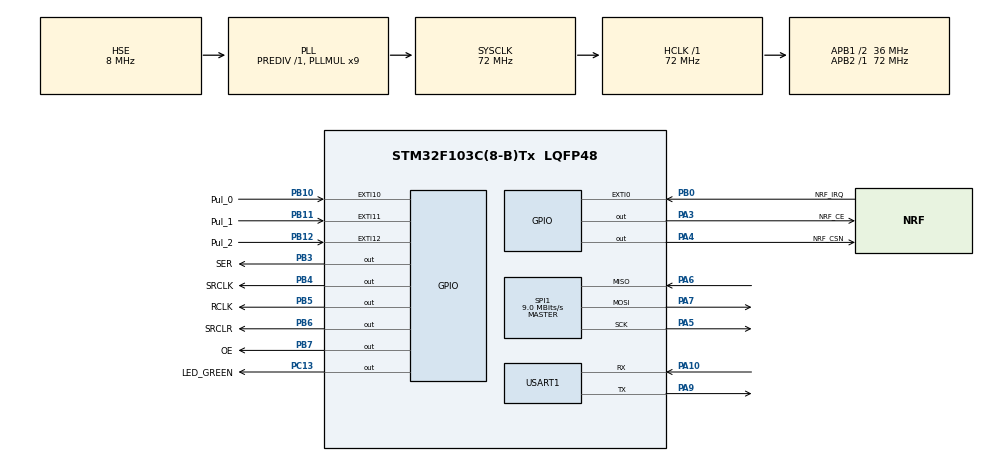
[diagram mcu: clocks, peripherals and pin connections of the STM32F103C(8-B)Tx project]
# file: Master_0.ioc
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Dma.Request0=SPI1_RX
Dma.Request1=SPI1_TX
Dma.Request2=USART1_TX
Dma.SPI1_RX.0.Direction=DMA_PERIPH_TO_MEMORY
Dma.SPI1_RX.0.Instance=DMA1_Channel2
Dma.SPI1_RX.0.MemDataAlignment=DMA_MDATAALIGN_BYTE
Dma.SPI1_RX.0.MemInc=DMA_MINC_ENABLE
Dma.SPI1_RX.0.Mode=DMA_NORMAL
Dma.SPI1_RX.0.PeriphDataAlignment=DMA_PDATAALIGN_BYTE
Dma.SPI1_RX.0.PeriphInc=DMA_PINC_DISABLE
Dma.SPI1_RX.0.Priority=DMA_PRIORITY_LOW
Dma.SPI1_TX.1.Direction=DMA_MEMORY_TO_PERIPH
Dma.SPI1_TX.1.Instance=DMA1_Channel3
Dma.SPI1_TX.1.MemDataAlignment=DMA_MDATAALIGN_BYTE
Dma.SPI1_TX.1.MemInc=DMA_MINC_ENABLE
Dma.SPI1_TX.1.Mode=DMA_NORMAL
Dma.SPI1_TX.1.PeriphDataAlignment=DMA_PDATAALIGN_BYTE
Dma.SPI1_TX.1.PeriphInc=DMA_PINC_DISABLE
Dma.SPI1_TX.1.Priority=DMA_PRIORITY_LOW
Dma.USART1_TX.2.Direction=DMA_MEMORY_TO_PERIPH
Dma.USART1_TX.2.Instance=DMA1_Channel4
Dma.USART1_TX.2.MemDataAlignment=DMA_MDATAALIGN_BYTE
Dma.USART1_TX.2.MemInc=DMA_MINC_ENABLE
Dma.USART1_TX.2.Mode=DMA_NORMAL
Dma.USART1_TX.2.PeriphDataAlignment=DMA_PDATAALIGN_BYTE
Dma.USART1_TX.2.PeriphInc=DMA_PINC_DISABLE
Dma.USART1_TX.2.Priority=DMA_PRIORITY_LOW
Mcu.Family=STM32F1
Mcu.Name=STM32F103C(8-B)Tx
Mcu.Package=LQFP48
NVIC.DMA1_Channel2_IRQn=true\:0\:0\:false\:false\:true\:false\:true\:true
NVIC.DMA1_Channel3_IRQn=true\:0\:0\:false\:false\:true\:false\:true\:true
NVIC.DMA1_Channel4_IRQn=true\:0\:0\:false\:false\:true\:false\:true\:true
NVIC.EXTI0_IRQn=true\:0\:0\:false\:false\:true\:true\:true\:true
NVIC.EXTI15_10_IRQn=true\:0\:0\:false\:false\:true\:true\:true\:true
NVIC.PriorityGroup=NVIC_PRIORITYGROUP_4
NVIC.USART1_IRQn=true\:0\:0\:false\:false\:true\:false\:true\:true
PA10.Mode=Asynchronous
PA10.Signal=USART1_RX
PA13.Mode=Serial_Wire
PA13.Signal=SYS_JTMS-SWDIO
PA14.Mode=Serial_Wire
PA14.Signal=SYS_JTCK-SWCLK
PA3.GPIO_Label=NRF_CE
PA3.Signal=GPIO_Output
PA4.GPIO_Label=NRF_CSN
PA4.GPIO_Speed=GPIO_SPEED_FREQ_LOW
PA4.PinState=GPIO_PIN_SET
PA4.Signal=GPIO_Output
PA5.Mode=Full_Duplex_Master
PA5.Signal=SPI1_SCK
PA6.Mode=Full_Duplex_Master
PA6.Signal=SPI1_MISO
PA7.Mode=Full_Duplex_Master
PA7.Signal=SPI1_MOSI
PA9.Mode=Asynchronous
PA9.Signal=USART1_TX
PB0.GPIO_Label=NRF_IRQ
PB0.GPIO_ModeDefaultEXTI=GPIO_MODE_IT_FALLING
PB0.GPIO_PuPd=GPIO_PULLUP
PB0.Signal=GPXTI0
PB10.GPIO_Label=Pul_0
PB10.GPIO_ModeDefaultEXTI=GPIO_MODE_IT_FALLING
PB10.GPIO_PuPd=GPIO_PULLUP
PB10.Signal=GPXTI10
PB11.GPIO_Label=Pul_1
PB11.GPIO_ModeDefaultEXTI=GPIO_MODE_IT_FALLING
PB11.GPIO_PuPd=GPIO_PULLUP
PB11.Signal=GPXTI11
PB12.GPIO_Label=Pul_2
PB12.GPIO_ModeDefaultEXTI=GPIO_MODE_IT_FALLING
PB12.GPIO_PuPd=GPIO_PULLUP
PB12.Signal=GPXTI12
PB3.GPIO_Label=SER
PB3.Signal=GPIO_Output
PB4.GPIO_Label=SRCLK
PB4.Signal=GPIO_Output
PB5.GPIO_Label=RCLK
PB5.Signal=GPIO_Output
PB6.GPIO_Label=SRCLR
PB6.PinState=GPIO_PIN_SET
PB6.Signal=GPIO_Output
PB7.GPIO_Label=OE
PB7.Signal=GPIO_Output
PC13-TAMPER-RTC.GPIO_Label=LED_GREEN
PC13-TAMPER-RTC.Signal=GPIO_Output
PD0-OSC_IN.Mode=HSE-External-Oscillator
PD0-OSC_IN.Signal=RCC_OSC_IN
PD1-OSC_OUT.Mode=HSE-External-Oscillator
PD1-OSC_OUT.Signal=RCC_OSC_OUT
ProjectManager.HeapSize=0x200
ProjectManager.StackSize=0x400
ProjectManager.TargetToolchain=STM32CubeIDE
RCC.AHBFreq_Value=72000000
RCC.APB1CLKDivider=RCC_HCLK_DIV2
RCC.APB1Freq_Value=36000000
RCC.APB1TimFreq_Value=72000000
RCC.APB2Freq_Value=72000000
RCC.APB2TimFreq_Value=72000000
RCC.HCLKFreq_Value=72000000
RCC.PLLMUL=RCC_PLL_MUL9
RCC.PLLSourceVirtual=RCC_PLLSOURCE_HSE
RCC.SYSCLKFreq_VALUE=72000000
RCC.SYSCLKSource=RCC_SYSCLKSOURCE_PLLCLK
RCC.USBFreq_Value=72000000
SPI1.BaudRatePrescaler=SPI_BAUDRATEPRESCALER_8
SPI1.CalculateBaudRate=9.0 MBits/s
SPI1.Direction=SPI_DIRECTION_2LINES
SPI1.Mode=SPI_MODE_MASTER
SPI1.VirtualType=VM_MASTER
USART1.VirtualMode=VM_ASYNC
board=custom

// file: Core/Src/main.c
/* USER CODE BEGIN Header */
/**
  ******************************************************************************
  * @file           : main.c
  * @brief          : Main program body
  ******************************************************************************
  * @attention
  *
  * Copyright (c) 2026 STMicroelectronics.
  * All rights reserved.
  *
  * This software is licensed under terms that can be found in the LICENSE file
  * in the root directory of this software component.
  * If no LICENSE file comes with this software, it is provided AS-IS.
  *
  *
  * 					MASTER
  *
  ******************************************************************************
  */
/* USER CODE END Header */
#include "main.h"
#include "dma.h"
#include "spi.h"
#include "usart.h"
#include "gpio.h"
#include "ports_master.h"

/* USER CODE BEGIN Includes */
#include "API_display.h"
#include "nrf24l01.h"
#include "API_parser.h"
/* USER CODE END Includes */

void SystemClock_Config(void);

int main(void)
{

  /* MCU Configuration--------------------------------------------------------*/

  /* Reset of all peripherals, Initializes the Flash interface and the Systick. */
  HAL_Init();
  HAL_Delay(300);			//Retardo bloqueante para darle tiempo a las fuentes que se estabilicen

  /* Configure the system clock */
  SystemClock_Config();

  /* Initialize all configured peripherals */
  MX_GPIO_Init();
  MX_DMA_Init();
  MX_SPI1_Init();
  MX_USART1_UART_Init();
  /* USER CODE BEGIN 2 */

  initParser(&huart1, &hspi1);

  /* USER CODE END 2 */

  /* Infinite loop */
  while (1)
  {

    /* USER CODE BEGIN 3 */
	  parserUpdate();
  }
  /* USER CODE END 3 */
}

void SystemClock_Config(void)
{
  RCC_OscInitTypeDef RCC_OscInitStruct = {0};
  RCC_ClkInitTypeDef RCC_ClkInitStruct = {0};

  /** Initializes the RCC Oscillators according to the specified parameters
  * in the RCC_OscInitTypeDef structure.
  */
  RCC_OscInitStruct.OscillatorType = RCC_OSCILLATORTYPE_HSE;
  RCC_OscInitStruct.HSEState = RCC_HSE_ON;
  RCC_OscInitStruct.HSEPredivValue = RCC_HSE_PREDIV_DIV1;
  RCC_OscInitStruct.HSIState = RCC_HSI_ON;
  RCC_OscInitStruct.PLL.PLLState = RCC_PLL_ON;
  RCC_OscInitStruct.PLL.PLLSource = RCC_PLLSOURCE_HSE;
  RCC_OscInitStruct.PLL.PLLMUL = RCC_PLL_MUL9;
  if (HAL_RCC_OscConfig(&RCC_OscInitStruct) != HAL_OK)
  {
    Error_Handler();
  }

  /** Initializes the CPU, AHB and APB buses clocks
  */
  RCC_ClkInitStruct.ClockType = RCC_CLOCKTYPE_HCLK|RCC_CLOCKTYPE_SYSCLK
                              |RCC_CLOCKTYPE_PCLK1|RCC_CLOCKTYPE_PCLK2;
  RCC_ClkInitStruct.SYSCLKSource = RCC_SYSCLKSOURCE_PLLCLK;
  RCC_ClkInitStruct.AHBCLKDivider = RCC_SYSCLK_DIV1;
  RCC_ClkInitStruct.APB1CLKDivider = RCC_HCLK_DIV2;
  RCC_ClkInitStruct.APB2CLKDivider = RCC_HCLK_DIV1;

  if (HAL_RCC_ClockConfig(&RCC_ClkInitStruct, FLASH_LATENCY_2) != HAL_OK)
  {
    Error_Handler();
  }
}

void Error_Handler(void)
{
  __disable_irq();
  while (1)
  {
  }
}
